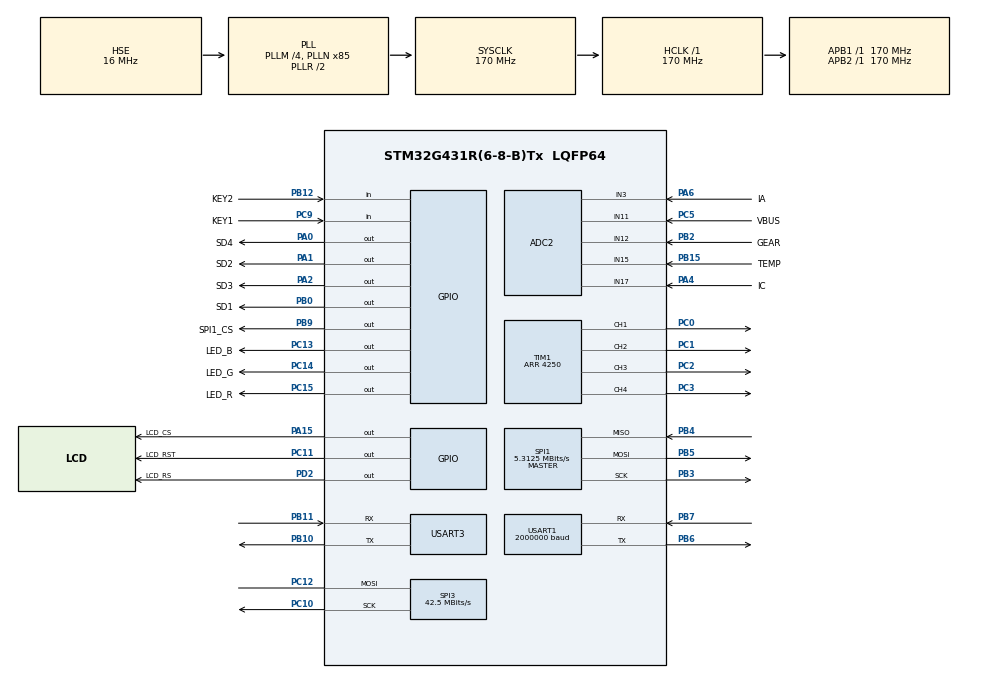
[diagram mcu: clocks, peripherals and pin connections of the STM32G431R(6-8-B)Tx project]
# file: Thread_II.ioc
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ADC2.Channel-0\#ChannelRegularConversion=ADC_CHANNEL_11
ADC2.Channel-4\#ChannelRegularConversion=ADC_CHANNEL_12
ADC2.Channel-8\#ChannelRegularConversion=ADC_CHANNEL_15
ADC2.ContinuousConvMode=ENABLE
ADC2.DMAContinuousRequests=ENABLE
ADC2.EnableInjectedConversion=ENABLE
ADC2.InjNumberOfConversion=2
ADC2.InjectedChannel-1\#ChannelInjectedConversion=ADC_CHANNEL_3
ADC2.InjectedChannel-7\#ChannelInjectedConversion=ADC_CHANNEL_17
ADC2.InjectedOffsetNumber-1\#ChannelInjectedConversion=ADC_OFFSET_NONE
ADC2.InjectedOffsetNumber-7\#ChannelInjectedConversion=ADC_OFFSET_NONE
ADC2.InjectedRank-1\#ChannelInjectedConversion=1
ADC2.InjectedRank-7\#ChannelInjectedConversion=2
ADC2.InjectedSamplingTime-1\#ChannelInjectedConversion=ADC_SAMPLETIME_2CYCLES_5
ADC2.InjectedSamplingTime-7\#ChannelInjectedConversion=ADC_SAMPLETIME_2CYCLES_5
ADC2.NbrOfConversion=3
ADC2.NbrOfConversionFlag=1
ADC2.OffsetNumber-0\#ChannelRegularConversion=ADC_OFFSET_NONE
ADC2.OffsetNumber-4\#ChannelRegularConversion=ADC_OFFSET_NONE
ADC2.OffsetNumber-8\#ChannelRegularConversion=ADC_OFFSET_NONE
ADC2.Rank-0\#ChannelRegularConversion=1
ADC2.Rank-4\#ChannelRegularConversion=2
ADC2.Rank-8\#ChannelRegularConversion=3
ADC2.SamplingTime-0\#ChannelRegularConversion=ADC_SAMPLETIME_92CYCLES_5
ADC2.SamplingTime-4\#ChannelRegularConversion=ADC_SAMPLETIME_92CYCLES_5
ADC2.SamplingTime-8\#ChannelRegularConversion=ADC_SAMPLETIME_92CYCLES_5
Dma.ADC2.0.Direction=DMA_PERIPH_TO_MEMORY
Dma.ADC2.0.EventEnable=DISABLE
Dma.ADC2.0.Instance=DMA1_Channel1
Dma.ADC2.0.MemDataAlignment=DMA_MDATAALIGN_HALFWORD
Dma.ADC2.0.MemInc=DMA_MINC_ENABLE
Dma.ADC2.0.Mode=DMA_CIRCULAR
Dma.ADC2.0.PeriphDataAlignment=DMA_PDATAALIGN_HALFWORD
Dma.ADC2.0.PeriphInc=DMA_PINC_DISABLE
Dma.ADC2.0.Polarity=HAL_DMAMUX_REQ_GEN_RISING
Dma.ADC2.0.Priority=DMA_PRIORITY_LOW
Dma.ADC2.0.RequestNumber=1
Dma.ADC2.0.SignalID=NONE
Dma.ADC2.0.SyncEnable=DISABLE
Dma.ADC2.0.SyncPolarity=HAL_DMAMUX_SYNC_NO_EVENT
Dma.ADC2.0.SyncRequestNumber=1
Dma.ADC2.0.SyncSignalID=NONE
Dma.Request0=ADC2
Dma.Request1=USART1_TX
Dma.USART1_TX.1.Direction=DMA_MEMORY_TO_PERIPH
Dma.USART1_TX.1.EventEnable=DISABLE
Dma.USART1_TX.1.Instance=DMA1_Channel2
Dma.USART1_TX.1.MemDataAlignment=DMA_MDATAALIGN_BYTE
Dma.USART1_TX.1.MemInc=DMA_MINC_ENABLE
Dma.USART1_TX.1.Mode=DMA_NORMAL
Dma.USART1_TX.1.PeriphDataAlignment=DMA_PDATAALIGN_BYTE
Dma.USART1_TX.1.PeriphInc=DMA_PINC_DISABLE
Dma.USART1_TX.1.Polarity=HAL_DMAMUX_REQ_GEN_RISING
Dma.USART1_TX.1.Priority=DMA_PRIORITY_LOW
Dma.USART1_TX.1.RequestNumber=1
Dma.USART1_TX.1.SignalID=NONE
Dma.USART1_TX.1.SyncEnable=DISABLE
Dma.USART1_TX.1.SyncPolarity=HAL_DMAMUX_SYNC_NO_EVENT
Dma.USART1_TX.1.SyncRequestNumber=1
Dma.USART1_TX.1.SyncSignalID=NONE
Mcu.Family=STM32G4
Mcu.Name=STM32G431R(6-8-B)Tx
Mcu.Package=LQFP64
NVIC.ADC1_2_IRQn=true\:1\:0\:true\:false\:true\:true\:true\:true
NVIC.DMA1_Channel1_IRQn=true\:0\:0\:false\:false\:true\:false\:true\:true
NVIC.DMA1_Channel2_IRQn=true\:0\:0\:false\:false\:true\:false\:true\:true
NVIC.PriorityGroup=NVIC_PRIORITYGROUP_4
NVIC.TIM1_UP_TIM16_IRQn=true\:0\:0\:false\:false\:true\:true\:true\:true
NVIC.USART1_IRQn=true\:3\:0\:true\:false\:true\:true\:true\:true
PA0.GPIO_Label=SD4
PA0.GPIO_Speed=GPIO_SPEED_FREQ_VERY_HIGH
PA0.Signal=GPIO_Output
PA1.GPIO_Label=SD2
PA1.GPIO_Speed=GPIO_SPEED_FREQ_VERY_HIGH
PA1.Signal=GPIO_Output
PA13.Mode=Serial_Wire
PA13.Signal=SYS_JTMS-SWDIO
PA14.Mode=Serial_Wire
PA14.Signal=SYS_JTCK-SWCLK
PA15.GPIO_Label=LCD_CS
PA15.GPIO_Speed=GPIO_SPEED_FREQ_VERY_HIGH
PA15.PinState=GPIO_PIN_SET
PA15.Signal=GPIO_Output
PA2.GPIO_Label=SD3
PA2.GPIO_Speed=GPIO_SPEED_FREQ_VERY_HIGH
PA2.Signal=GPIO_Output
PA4.GPIO_Label=IC
PA4.Mode=IN17-Single-Ended
PA4.Signal=ADC2_IN17
PA6.GPIO_Label=IA
PA6.Mode=IN3-Single-Ended
PA6.Signal=ADC2_IN3
PB0.GPIO_Label=SD1
PB0.GPIO_Speed=GPIO_SPEED_FREQ_VERY_HIGH
PB0.Signal=GPIO_Output
PB10.Mode=Asynchronous
PB10.Signal=USART3_TX
PB11.Mode=Asynchronous
PB11.Signal=USART3_RX
PB12.GPIO_Label=KEY2
PB12.GPIO_PuPd=GPIO_NOPULL
PB12.Signal=GPIO_Input
PB15.GPIO_Label=TEMP
PB15.Mode=IN15-Single-Ended
PB15.Signal=ADC2_IN15
PB2.GPIO_Label=GEAR
PB2.Mode=IN12-Single-Ended
PB2.Signal=ADC2_IN12
PB3.GPIO_Speed=GPIO_SPEED_FREQ_VERY_HIGH
PB3.Mode=Full_Duplex_Master
PB3.Signal=SPI1_SCK
PB4.GPIO_PuPd=GPIO_PULLUP
PB4.GPIO_Speed=GPIO_SPEED_FREQ_VERY_HIGH
PB4.Mode=Full_Duplex_Master
PB4.Signal=SPI1_MISO
PB5.GPIO_Speed=GPIO_SPEED_FREQ_VERY_HIGH
PB5.Mode=Full_Duplex_Master
PB5.Signal=SPI1_MOSI
PB6.GPIO_Speed=GPIO_SPEED_FREQ_VERY_HIGH
PB6.Mode=Asynchronous
PB6.Signal=USART1_TX
PB7.GPIO_Speed=GPIO_SPEED_FREQ_VERY_HIGH
PB7.Mode=Asynchronous
PB7.Signal=USART1_RX
PB9.GPIO_FM9=SYSCFG_FASTMODEPLUS_PB9
PB9.GPIO_Label=SPI1_CS
PB9.GPIO_PuPd=GPIO_PULLUP
PB9.GPIO_Speed=GPIO_SPEED_FREQ_VERY_HIGH
PB9.PinState=GPIO_PIN_SET
PB9.Signal=GPIO_Output
PC0.GPIO_Speed=GPIO_SPEED_FREQ_VERY_HIGH
PC0.Signal=S_TIM1_CH1
PC1.GPIO_Speed=GPIO_SPEED_FREQ_VERY_HIGH
PC1.Signal=S_TIM1_CH2
PC10.GPIO_Speed=GPIO_SPEED_FREQ_VERY_HIGH
PC10.Mode=Simplex_Bidirectional_Master
PC10.Signal=SPI3_SCK
PC11.GPIO_Label=LCD_RST
PC11.GPIO_Speed=GPIO_SPEED_FREQ_VERY_HIGH
PC11.Signal=GPIO_Output
PC12.GPIO_Speed=GPIO_SPEED_FREQ_VERY_HIGH
PC12.Mode=Simplex_Bidirectional_Master
PC12.Signal=SPI3_MOSI
PC13.GPIO_Label=LED_B
PC13.GPIO_PuPd=GPIO_NOPULL
PC13.PinState=GPIO_PIN_SET
PC13.Signal=GPIO_Output
PC14-OSC32_IN.GPIO_Label=LED_G
PC14-OSC32_IN.PinState=GPIO_PIN_SET
PC14-OSC32_IN.Signal=GPIO_Output
PC15-OSC32_OUT.GPIO_Label=LED_R
PC15-OSC32_OUT.PinState=GPIO_PIN_SET
PC15-OSC32_OUT.Signal=GPIO_Output
PC2.GPIO_Speed=GPIO_SPEED_FREQ_VERY_HIGH
PC2.Signal=S_TIM1_CH3
PC3.GPIO_Speed=GPIO_SPEED_FREQ_VERY_HIGH
PC3.Signal=S_TIM1_CH4
PC5.GPIO_Label=VBUS
PC5.Mode=IN11-Single-Ended
PC5.Signal=ADC2_IN11
PC9.GPIO_Label=KEY1
PC9.GPIO_PuPd=GPIO_NOPULL
PC9.Signal=GPIO_Input
PD2.GPIO_Label=LCD_RS
PD2.GPIO_Speed=GPIO_SPEED_FREQ_VERY_HIGH
PD2.Signal=GPIO_Output
PF0-OSC_IN.Mode=HSE-External-Oscillator
PF0-OSC_IN.Signal=RCC_OSC_IN
PF1-OSC_OUT.Mode=HSE-External-Oscillator
PF1-OSC_OUT.Signal=RCC_OSC_OUT
ProjectManager.HeapSize=0x200
ProjectManager.StackSize=0x400
ProjectManager.TargetToolchain=EWARM V8.50
RCC.ADC12Freq_Value=170000000
RCC.AHBFreq_Value=170000000
RCC.APB1Freq_Value=170000000
RCC.APB1TimFreq_Value=170000000
RCC.APB2Freq_Value=170000000
RCC.APB2TimFreq_Value=170000000
RCC.CortexFreq_Value=170000000
RCC.EXTERNAL_CLOCK_VALUE=12288000
RCC.HCLKFreq_Value=170000000
RCC.HSE_VALUE=16000000
RCC.HSI48_VALUE=48000000
RCC.HSI_VALUE=16000000
RCC.LSE_VALUE=32768
RCC.PLLM=RCC_PLLM_DIV4
RCC.PLLN=85
RCC.PLLSourceVirtual=RCC_PLLSOURCE_HSE
RCC.SYSCLKFreq_VALUE=170000000
RCC.SYSCLKSource=RCC_SYSCLKSOURCE_PLLCLK
RCC.USBFreq_Value=170000000
RCC.VCOOutputFreq_Value=340000000
SH.S_TIM1_CH1.0=TIM1_CH1,PWM Generation1 CH1
SH.S_TIM1_CH2.0=TIM1_CH2,PWM Generation2 CH2
SH.S_TIM1_CH3.0=TIM1_CH3,PWM Generation3 CH3
SH.S_TIM1_CH4.0=TIM1_CH4,PWM Generation4 CH4
SPI1.BaudRatePrescaler=SPI_BAUDRATEPRESCALER_32
SPI1.CLKPhase=SPI_PHASE_2EDGE
SPI1.CLKPolarity=SPI_POLARITY_HIGH
SPI1.CalculateBaudRate=5.3125 MBits/s
SPI1.DataSize=SPI_DATASIZE_16BIT
SPI1.Direction=SPI_DIRECTION_2LINES
SPI1.Mode=SPI_MODE_MASTER
SPI1.VirtualType=VM_MASTER
SPI3.BaudRatePrescaler=SPI_BAUDRATEPRESCALER_4
SPI3.CalculateBaudRate=42.5 MBits/s
SPI3.DataSize=SPI_DATASIZE_8BIT
SPI3.Direction=SPI_DIRECTION_1LINE
SPI3.Mode=SPI_MODE_MASTER
SPI3.VirtualType=VM_MASTER
TIM1.AutoReloadPreload=TIM_AUTORELOAD_PRELOAD_ENABLE
TIM1.Channel-PWM\ Generation1\ CH1=TIM_CHANNEL_1
TIM1.Channel-PWM\ Generation2\ CH2=TIM_CHANNEL_2
TIM1.Channel-PWM\ Generation3\ CH3=TIM_CHANNEL_3
TIM1.Channel-PWM\ Generation4\ CH4=TIM_CHANNEL_4
TIM1.CounterMode=TIM_COUNTERMODE_CENTERALIGNED1
TIM1.OCMode_PWM-PWM\ Generation1\ CH1=TIM_OCMODE_PWM2
TIM1.OCMode_PWM-PWM\ Generation2\ CH2=TIM_OCMODE_PWM2
TIM1.OCMode_PWM-PWM\ Generation3\ CH3=TIM_OCMODE_PWM2
TIM1.OCMode_PWM-PWM\ Generation4\ CH4=TIM_OCMODE_PWM2
TIM1.PeriodNoDither=4250
TIM1.RepetitionCounter=1
USART1.BaudRate=2000000
USART1.VirtualMode-Asynchronous=VM_ASYNC
USART3.VirtualMode-Asynchronous=VM_ASYNC
VP_SYS_VS_DBSignals.Mode=DisableDeadBatterySignals
VP_TIM1_VS_ClockSourceINT.Mode=Internal
board=custom

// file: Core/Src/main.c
/* USER CODE BEGIN Header */
/**
  ******************************************************************************
  * @file           : main.c
  * @brief          : Main program body
  ******************************************************************************
  * @attention
  *
  * Copyright (c) 2026 STMicroelectronics.
  * All rights reserved.
  *
  * This software is licensed under terms that can be found in the LICENSE file
  * in the root directory of this software component.
  * If no LICENSE file comes with this software, it is provided AS-IS.
  *
  ******************************************************************************
  */
/* USER CODE END Header */
#include "main.h"

ADC_HandleTypeDef hadc2;
DMA_HandleTypeDef hdma_adc2;

SPI_HandleTypeDef hspi1;
SPI_HandleTypeDef hspi3;

TIM_HandleTypeDef htim1;

UART_HandleTypeDef huart1;
UART_HandleTypeDef huart3;
DMA_HandleTypeDef hdma_usart1_tx;

void SystemClock_Config(void);
static void MX_GPIO_Init(void);
static void MX_DMA_Init(void);
static void MX_ADC2_Init(void);
static void MX_TIM1_Init(void);
static void MX_SPI3_Init(void);
static void MX_USART1_UART_Init(void);
static void MX_USART3_UART_Init(void);
static void MX_SPI1_Init(void);
/* USER CODE BEGIN PFP */
extern void task_loop(void);

/* USER CODE END PFP */

/* USER CODE BEGIN 0 */
size_t __write(int handle, const unsigned char *buffer, size_t size)
{
    HAL_UART_Transmit(&huart3, (uint8_t *)buffer, size, 10);

    return size;
}

/* USER CODE END 0 */

int main(void)
{

  /* MCU Configuration--------------------------------------------------------*/

  /* Reset of all peripherals, Initializes the Flash interface and the Systick. */
  HAL_Init();

  /* Configure the system clock */
  SystemClock_Config();

  /* Initialize all configured peripherals */
  MX_GPIO_Init();
  MX_DMA_Init();
  MX_ADC2_Init();
  MX_TIM1_Init();
  MX_SPI3_Init();
  MX_USART1_UART_Init();
  MX_USART3_UART_Init();
  MX_SPI1_Init();

  /* Infinite loop */
  while (1)
  {

    /* USER CODE BEGIN 3 */
	task_loop();
  }
  /* USER CODE END 3 */
}

void SystemClock_Config(void)
{
  RCC_OscInitTypeDef RCC_OscInitStruct = {0};
  RCC_ClkInitTypeDef RCC_ClkInitStruct = {0};

  /** Configure the main internal regulator output voltage
  */
  HAL_PWREx_ControlVoltageScaling(PWR_REGULATOR_VOLTAGE_SCALE1_BOOST);

  /** Initializes the RCC Oscillators according to the specified parameters
  * in the RCC_OscInitTypeDef structure.
  */
  RCC_OscInitStruct.OscillatorType = RCC_OSCILLATORTYPE_HSE;
  RCC_OscInitStruct.HSEState = RCC_HSE_ON;
  RCC_OscInitStruct.PLL.PLLState = RCC_PLL_ON;
  RCC_OscInitStruct.PLL.PLLSource = RCC_PLLSOURCE_HSE;
  RCC_OscInitStruct.PLL.PLLM = RCC_PLLM_DIV4;
  RCC_OscInitStruct.PLL.PLLN = 85;
  RCC_OscInitStruct.PLL.PLLP = RCC_PLLP_DIV2;
  RCC_OscInitStruct.PLL.PLLQ = RCC_PLLQ_DIV2;
  RCC_OscInitStruct.PLL.PLLR = RCC_PLLR_DIV2;
  if (HAL_RCC_OscConfig(&RCC_OscInitStruct) != HAL_OK)
  {
    Error_Handler();
  }

  /** Initializes the CPU, AHB and APB buses clocks
  */
  RCC_ClkInitStruct.ClockType = RCC_CLOCKTYPE_HCLK|RCC_CLOCKTYPE_SYSCLK
                              |RCC_CLOCKTYPE_PCLK1|RCC_CLOCKTYPE_PCLK2;
  RCC_ClkInitStruct.SYSCLKSource = RCC_SYSCLKSOURCE_PLLCLK;
  RCC_ClkInitStruct.AHBCLKDivider = RCC_SYSCLK_DIV1;
  RCC_ClkInitStruct.APB1CLKDivider = RCC_HCLK_DIV1;
  RCC_ClkInitStruct.APB2CLKDivider = RCC_HCLK_DIV1;

  if (HAL_RCC_ClockConfig(&RCC_ClkInitStruct, FLASH_LATENCY_4) != HAL_OK)
  {
    Error_Handler();
  }
}

static void MX_ADC2_Init(void)
{

  ADC_ChannelConfTypeDef sConfig = {0};
  ADC_InjectionConfTypeDef sConfigInjected = {0};

  /** Common config
  */
  hadc2.Instance = ADC2;
  hadc2.Init.ClockPrescaler = ADC_CLOCK_SYNC_PCLK_DIV4;
  hadc2.Init.Resolution = ADC_RESOLUTION_12B;
  hadc2.Init.DataAlign = ADC_DATAALIGN_RIGHT;
  hadc2.Init.GainCompensation = 0;
  hadc2.Init.ScanConvMode = ADC_SCAN_ENABLE;
  hadc2.Init.EOCSelection = ADC_EOC_SINGLE_CONV;
  hadc2.Init.LowPowerAutoWait = DISABLE;
  hadc2.Init.ContinuousConvMode = ENABLE;
  hadc2.Init.NbrOfConversion = 3;
  hadc2.Init.DiscontinuousConvMode = DISABLE;
  hadc2.Init.ExternalTrigConv = ADC_SOFTWARE_START;
  hadc2.Init.ExternalTrigConvEdge = ADC_EXTERNALTRIGCONVEDGE_NONE;
  hadc2.Init.DMAContinuousRequests = ENABLE;
  hadc2.Init.Overrun = ADC_OVR_DATA_PRESERVED;
  hadc2.Init.OversamplingMode = DISABLE;
  if (HAL_ADC_Init(&hadc2) != HAL_OK)
  {
    Error_Handler();
  }

  /** Configure Regular Channel
  */
  sConfig.Channel = ADC_CHANNEL_11;
  sConfig.Rank = ADC_REGULAR_RANK_1;
  sConfig.SamplingTime = ADC_SAMPLETIME_92CYCLES_5;
  sConfig.SingleDiff = ADC_SINGLE_ENDED;
  sConfig.OffsetNumber = ADC_OFFSET_NONE;
  sConfig.Offset = 0;
  if (HAL_ADC_ConfigChannel(&hadc2, &sConfig) != HAL_OK)
  {
    Error_Handler();
  }

  /** Configure Regular Channel
  */
  sConfig.Channel = ADC_CHANNEL_12;
  sConfig.Rank = ADC_REGULAR_RANK_2;
  if (HAL_ADC_ConfigChannel(&hadc2, &sConfig) != HAL_OK)
  {
    Error_Handler();
  }

  /** Configure Regular Channel
  */
  sConfig.Channel = ADC_CHANNEL_15;
  sConfig.Rank = ADC_REGULAR_RANK_3;
  if (HAL_ADC_ConfigChannel(&hadc2, &sConfig) != HAL_OK)
  {
    Error_Handler();
  }

  /** Configure Injected Channel
  */
  sConfigInjected.InjectedChannel = ADC_CHANNEL_3;
  sConfigInjected.InjectedRank = ADC_INJECTED_RANK_1;
  sConfigInjected.InjectedSamplingTime = ADC_SAMPLETIME_2CYCLES_5;
  sConfigInjected.InjectedSingleDiff = ADC_SINGLE_ENDED;
  sConfigInjected.InjectedOffsetNumber = ADC_OFFSET_NONE;
  sConfigInjected.InjectedOffset = 0;
  sConfigInjected.InjectedNbrOfConversion = 2;
  sConfigInjected.InjectedDiscontinuousConvMode = DISABLE;
  sConfigInjected.AutoInjectedConv = DISABLE;
  sConfigInjected.QueueInjectedContext = DISABLE;
  sConfigInjected.ExternalTrigInjecConv = ADC_INJECTED_SOFTWARE_START;
  sConfigInjected.ExternalTrigInjecConvEdge = ADC_EXTERNALTRIGINJECCONV_EDGE_NONE;
  sConfigInjected.InjecOversamplingMode = DISABLE;
  if (HAL_ADCEx_InjectedConfigChannel(&hadc2, &sConfigInjected) != HAL_OK)
  {
    Error_Handler();
  }

  /** Configure Injected Channel
  */
  sConfigInjected.InjectedChannel = ADC_CHANNEL_17;
  sConfigInjected.InjectedRank = ADC_INJECTED_RANK_2;
  if (HAL_ADCEx_InjectedConfigChannel(&hadc2, &sConfigInjected) != HAL_OK)
  {
    Error_Handler();
  }

}

static void MX_SPI1_Init(void)
{

  /* SPI1 parameter configuration*/
  hspi1.Instance = SPI1;
  hspi1.Init.Mode = SPI_MODE_MASTER;
  hspi1.Init.Direction = SPI_DIRECTION_2LINES;
  hspi1.Init.DataSize = SPI_DATASIZE_16BIT;
  hspi1.Init.CLKPolarity = SPI_POLARITY_HIGH;
  hspi1.Init.CLKPhase = SPI_PHASE_2EDGE;
  hspi1.Init.NSS = SPI_NSS_SOFT;
  hspi1.Init.BaudRatePrescaler = SPI_BAUDRATEPRESCALER_32;
  hspi1.Init.FirstBit = SPI_FIRSTBIT_MSB;
  hspi1.Init.TIMode = SPI_TIMODE_DISABLE;
  hspi1.Init.CRCCalculation = SPI_CRCCALCULATION_DISABLE;
  hspi1.Init.CRCPolynomial = 7;
  hspi1.Init.CRCLength = SPI_CRC_LENGTH_DATASIZE;
  hspi1.Init.NSSPMode = SPI_NSS_PULSE_DISABLE;
  if (HAL_SPI_Init(&hspi1) != HAL_OK)
  {
    Error_Handler();
  }

}

static void MX_SPI3_Init(void)
{

  /* SPI3 parameter configuration*/
  hspi3.Instance = SPI3;
  hspi3.Init.Mode = SPI_MODE_MASTER;
  hspi3.Init.Direction = SPI_DIRECTION_1LINE;
  hspi3.Init.DataSize = SPI_DATASIZE_8BIT;
  hspi3.Init.CLKPolarity = SPI_POLARITY_LOW;
  hspi3.Init.CLKPhase = SPI_PHASE_1EDGE;
  hspi3.Init.NSS = SPI_NSS_SOFT;
  hspi3.Init.BaudRatePrescaler = SPI_BAUDRATEPRESCALER_4;
  hspi3.Init.FirstBit = SPI_FIRSTBIT_MSB;
  hspi3.Init.TIMode = SPI_TIMODE_DISABLE;
  hspi3.Init.CRCCalculation = SPI_CRCCALCULATION_DISABLE;
  hspi3.Init.CRCPolynomial = 7;
  hspi3.Init.CRCLength = SPI_CRC_LENGTH_DATASIZE;
  hspi3.Init.NSSPMode = SPI_NSS_PULSE_ENABLE;
  if (HAL_SPI_Init(&hspi3) != HAL_OK)
  {
    Error_Handler();
  }

}

static void MX_TIM1_Init(void)
{

  TIM_ClockConfigTypeDef sClockSourceConfig = {0};
  TIM_MasterConfigTypeDef sMasterConfig = {0};
  TIM_OC_InitTypeDef sConfigOC = {0};
  TIM_BreakDeadTimeConfigTypeDef sBreakDeadTimeConfig = {0};

  htim1.Instance = TIM1;
  htim1.Init.Prescaler = 0;
  htim1.Init.CounterMode = TIM_COUNTERMODE_CENTERALIGNED1;
  htim1.Init.Period = 4250;
  htim1.Init.ClockDivision = TIM_CLOCKDIVISION_DIV1;
  htim1.Init.RepetitionCounter = 1;
  htim1.Init.AutoReloadPreload = TIM_AUTORELOAD_PRELOAD_ENABLE;
  if (HAL_TIM_Base_Init(&htim1) != HAL_OK)
  {
    Error_Handler();
  }
  sClockSourceConfig.ClockSource = TIM_CLOCKSOURCE_INTERNAL;
  if (HAL_TIM_ConfigClockSource(&htim1, &sClockSourceConfig) != HAL_OK)
  {
    Error_Handler();
  }
  if (HAL_TIM_PWM_Init(&htim1) != HAL_OK)
  {
    Error_Handler();
  }
  sMasterConfig.MasterOutputTrigger = TIM_TRGO_RESET;
  sMasterConfig.MasterOutputTrigger2 = TIM_TRGO2_RESET;
  sMasterConfig.MasterSlaveMode = TIM_MASTERSLAVEMODE_DISABLE;
  if (HAL_TIMEx_MasterConfigSynchronization(&htim1, &sMasterConfig) != HAL_OK)
  {
    Error_Handler();
  }
  sConfigOC.OCMode = TIM_OCMODE_PWM2;
  sConfigOC.Pulse = 0;
  sConfigOC.OCPolarity = TIM_OCPOLARITY_HIGH;
  sConfigOC.OCNPolarity = TIM_OCNPOLARITY_HIGH;
  sConfigOC.OCFastMode = TIM_OCFAST_DISABLE;
  sConfigOC.OCIdleState = TIM_OCIDLESTATE_RESET;
  sConfigOC.OCNIdleState = TIM_OCNIDLESTATE_RESET;
  if (HAL_TIM_PWM_ConfigChannel(&htim1, &sConfigOC, TIM_CHANNEL_1) != HAL_OK)
  {
    Error_Handler();
  }
  if (HAL_TIM_PWM_ConfigChannel(&htim1, &sConfigOC, TIM_CHANNEL_2) != HAL_OK)
  {
    Error_Handler();
  }
  if (HAL_TIM_PWM_ConfigChannel(&htim1, &sConfigOC, TIM_CHANNEL_3) != HAL_OK)
  {
    Error_Handler();
  }
  if (HAL_TIM_PWM_ConfigChannel(&htim1, &sConfigOC, TIM_CHANNEL_4) != HAL_OK)
  {
    Error_Handler();
  }
  sBreakDeadTimeConfig.OffStateRunMode = TIM_OSSR_DISABLE;
  sBreakDeadTimeConfig.OffStateIDLEMode = TIM_OSSI_DISABLE;
  sBreakDeadTimeConfig.LockLevel = TIM_LOCKLEVEL_OFF;
  sBreakDeadTimeConfig.DeadTime = 0;
  sBreakDeadTimeConfig.BreakState = TIM_BREAK_DISABLE;
  sBreakDeadTimeConfig.BreakPolarity = TIM_BREAKPOLARITY_HIGH;
  sBreakDeadTimeConfig.BreakFilter = 0;
  sBreakDeadTimeConfig.BreakAFMode = TIM_BREAK_AFMODE_INPUT;
  sBreakDeadTimeConfig.Break2State = TIM_BREAK2_DISABLE;
  sBreakDeadTimeConfig.Break2Polarity = TIM_BREAK2POLARITY_HIGH;
  sBreakDeadTimeConfig.Break2Filter = 0;
  sBreakDeadTimeConfig.Break2AFMode = TIM_BREAK_AFMODE_INPUT;
  sBreakDeadTimeConfig.AutomaticOutput = TIM_AUTOMATICOUTPUT_DISABLE;
  if (HAL_TIMEx_ConfigBreakDeadTime(&htim1, &sBreakDeadTimeConfig) != HAL_OK)
  {
    Error_Handler();
  }
  HAL_TIM_MspPostInit(&htim1);

}

static void MX_USART1_UART_Init(void)
{

  huart1.Instance = USART1;
  huart1.Init.BaudRate = 2000000;
  huart1.Init.WordLength = UART_WORDLENGTH_8B;
  huart1.Init.StopBits = UART_STOPBITS_1;
  huart1.Init.Parity = UART_PARITY_NONE;
  huart1.Init.Mode = UART_MODE_TX_RX;
  huart1.Init.HwFlowCtl = UART_HWCONTROL_NONE;
  huart1.Init.OverSampling = UART_OVERSAMPLING_16;
  huart1.Init.OneBitSampling = UART_ONE_BIT_SAMPLE_DISABLE;
  huart1.Init.ClockPrescaler = UART_PRESCALER_DIV1;
  huart1.AdvancedInit.AdvFeatureInit = UART_ADVFEATURE_NO_INIT;
  if (HAL_UART_Init(&huart1) != HAL_OK)
  {
    Error_Handler();
  }
  if (HAL_UARTEx_SetTxFifoThreshold(&huart1, UART_TXFIFO_THRESHOLD_1_8) != HAL_OK)
  {
    Error_Handler();
  }
  if (HAL_UARTEx_SetRxFifoThreshold(&huart1, UART_RXFIFO_THRESHOLD_1_8) != HAL_OK)
  {
    Error_Handler();
  }
  if (HAL_UARTEx_DisableFifoMode(&huart1) != HAL_OK)
  {
    Error_Handler();
  }

}

static void MX_USART3_UART_Init(void)
{

  huart3.Instance = USART3;
  huart3.Init.BaudRate = 115200;
  huart3.Init.WordLength = UART_WORDLENGTH_8B;
  huart3.Init.StopBits = UART_STOPBITS_1;
  huart3.Init.Parity = UART_PARITY_NONE;
  huart3.Init.Mode = UART_MODE_TX_RX;
  huart3.Init.HwFlowCtl = UART_HWCONTROL_NONE;
  huart3.Init.OverSampling = UART_OVERSAMPLING_16;
  huart3.Init.OneBitSampling = UART_ONE_BIT_SAMPLE_DISABLE;
  huart3.Init.ClockPrescaler = UART_PRESCALER_DIV1;
  huart3.AdvancedInit.AdvFeatureInit = UART_ADVFEATURE_NO_INIT;
  if (HAL_UART_Init(&huart3) != HAL_OK)
  {
    Error_Handler();
  }
  if (HAL_UARTEx_SetTxFifoThreshold(&huart3, UART_TXFIFO_THRESHOLD_1_8) != HAL_OK)
  {
    Error_Handler();
  }
  if (HAL_UARTEx_SetRxFifoThreshold(&huart3, UART_RXFIFO_THRESHOLD_1_8) != HAL_OK)
  {
    Error_Handler();
  }
  if (HAL_UARTEx_DisableFifoMode(&huart3) != HAL_OK)
  {
    Error_Handler();
  }

}

static void MX_DMA_Init(void)
{

  /* DMA controller clock enable */
  __HAL_RCC_DMAMUX1_CLK_ENABLE();
  __HAL_RCC_DMA1_CLK_ENABLE();

  /* DMA interrupt init */
  /* DMA1_Channel1_IRQn interrupt configuration */
  HAL_NVIC_SetPriority(DMA1_Channel1_IRQn, 0, 0);
  HAL_NVIC_EnableIRQ(DMA1_Channel1_IRQn);
  /* DMA1_Channel2_IRQn interrupt configuration */
  HAL_NVIC_SetPriority(DMA1_Channel2_IRQn, 0, 0);
  HAL_NVIC_EnableIRQ(DMA1_Channel2_IRQn);

}

static void MX_GPIO_Init(void)
{
  GPIO_InitTypeDef GPIO_InitStruct = {0};

  /* GPIO Ports Clock Enable */
  __HAL_RCC_GPIOC_CLK_ENABLE();
  __HAL_RCC_GPIOF_CLK_ENABLE();
  __HAL_RCC_GPIOA_CLK_ENABLE();
  __HAL_RCC_GPIOB_CLK_ENABLE();
  __HAL_RCC_GPIOD_CLK_ENABLE();

  /*Configure GPIO pin Output Level */
  HAL_GPIO_WritePin(GPIOC, LED_B_Pin|LED_G_Pin|LED_R_Pin, GPIO_PIN_SET);

  /*Configure GPIO pin Output Level */
  HAL_GPIO_WritePin(GPIOA, SD4_Pin|SD2_Pin|SD3_Pin, GPIO_PIN_RESET);

  /*Configure GPIO pin Output Level */
  HAL_GPIO_WritePin(SD1_GPIO_Port, SD1_Pin, GPIO_PIN_RESET);

  /*Configure GPIO pin Output Level */
  HAL_GPIO_WritePin(LCD_CS_GPIO_Port, LCD_CS_Pin, GPIO_PIN_SET);

  /*Configure GPIO pin Output Level */
  HAL_GPIO_WritePin(LCD_RST_GPIO_Port, LCD_RST_Pin, GPIO_PIN_RESET);

  /*Configure GPIO pin Output Level */
  HAL_GPIO_WritePin(LCD_RS_GPIO_Port, LCD_RS_Pin, GPIO_PIN_RESET);

  /*Configure GPIO pin Output Level */
  HAL_GPIO_WritePin(SPI1_CS_GPIO_Port, SPI1_CS_Pin, GPIO_PIN_SET);

  /*Configure GPIO pins : LED_B_Pin LED_G_Pin LED_R_Pin */
  GPIO_InitStruct.Pin = LED_B_Pin|LED_G_Pin|LED_R_Pin;
  GPIO_InitStruct.Mode = GPIO_MODE_OUTPUT_PP;
  GPIO_InitStruct.Pull = GPIO_NOPULL;
  GPIO_InitStruct.Speed = GPIO_SPEED_FREQ_LOW;
  HAL_GPIO_Init(GPIOC, &GPIO_InitStruct);

  /*Configure GPIO pins : SD4_Pin SD2_Pin SD3_Pin LCD_CS_Pin */
  GPIO_InitStruct.Pin = SD4_Pin|SD2_Pin|SD3_Pin|LCD_CS_Pin;
  GPIO_InitStruct.Mode = GPIO_MODE_OUTPUT_PP;
  GPIO_InitStruct.Pull = GPIO_NOPULL;
  GPIO_InitStruct.Speed = GPIO_SPEED_FREQ_VERY_HIGH;
  HAL_GPIO_Init(GPIOA, &GPIO_InitStruct);

  /*Configure GPIO pin : SD1_Pin */
  GPIO_InitStruct.Pin = SD1_Pin;
  GPIO_InitStruct.Mode = GPIO_MODE_OUTPUT_PP;
  GPIO_InitStruct.Pull = GPIO_NOPULL;
  GPIO_InitStruct.Speed = GPIO_SPEED_FREQ_VERY_HIGH;
  HAL_GPIO_Init(SD1_GPIO_Port, &GPIO_InitStruct);

  /*Configure GPIO pin : KEY2_Pin */
  GPIO_InitStruct.Pin = KEY2_Pin;
  GPIO_InitStruct.Mode = GPIO_MODE_INPUT;
  GPIO_InitStruct.Pull = GPIO_NOPULL;
  HAL_GPIO_Init(KEY2_GPIO_Port, &GPIO_InitStruct);

  /*Configure GPIO pin : KEY1_Pin */
  GPIO_InitStruct.Pin = KEY1_Pin;
  GPIO_InitStruct.Mode = GPIO_MODE_INPUT;
  GPIO_InitStruct.Pull = GPIO_NOPULL;
  HAL_GPIO_Init(KEY1_GPIO_Port, &GPIO_InitStruct);

  /*Configure GPIO pin : LCD_RST_Pin */
  GPIO_InitStruct.Pin = LCD_RST_Pin;
  GPIO_InitStruct.Mode = GPIO_MODE_OUTPUT_PP;
  GPIO_InitStruct.Pull = GPIO_NOPULL;
  GPIO_InitStruct.Speed = GPIO_SPEED_FREQ_VERY_HIGH;
  HAL_GPIO_Init(LCD_RST_GPIO_Port, &GPIO_InitStruct);

  /*Configure GPIO pin : LCD_RS_Pin */
  GPIO_InitStruct.Pin = LCD_RS_Pin;
  GPIO_InitStruct.Mode = GPIO_MODE_OUTPUT_PP;
  GPIO_InitStruct.Pull = GPIO_NOPULL;
  GPIO_InitStruct.Speed = GPIO_SPEED_FREQ_VERY_HIGH;
  HAL_GPIO_Init(LCD_RS_GPIO_Port, &GPIO_InitStruct);

  /*Configure GPIO pin : SPI1_CS_Pin */
  GPIO_InitStruct.Pin = SPI1_CS_Pin;
  GPIO_InitStruct.Mode = GPIO_MODE_OUTPUT_PP;
  GPIO_InitStruct.Pull = GPIO_PULLUP;
  GPIO_InitStruct.Speed = GPIO_SPEED_FREQ_VERY_HIGH;
  HAL_GPIO_Init(SPI1_CS_GPIO_Port, &GPIO_InitStruct);

  /**/
  __HAL_SYSCFG_FASTMODEPLUS_ENABLE(SYSCFG_FASTMODEPLUS_PB9);

}

void Error_Handler(void)
{
  __disable_irq();
  while (1)
  {
  }
}
